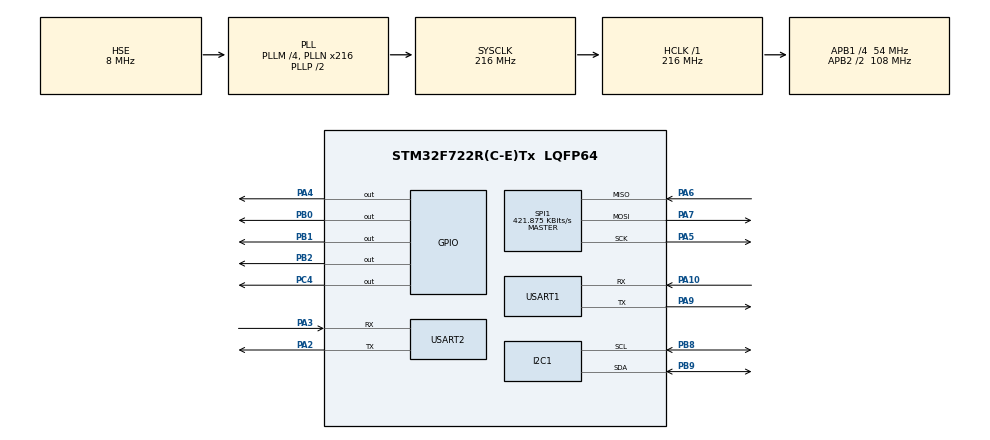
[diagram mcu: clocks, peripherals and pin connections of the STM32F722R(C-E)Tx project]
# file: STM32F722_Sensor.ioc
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CORTEX_M7.default_mode_Activation=1
FREERTOS.Tasks01=LED_FLASH,8,128,led_task,Default,NULL,Dynamic,NULL,NULL;UART_SEND,8,128,uart_task,As weak,NULL,Dynamic,NULL,NULL;IMU_DATA,8,128,imu_task,As weak,NULL,Dynamic,NULL,NULL;BARO_DATA,8,512,baro_task,As weak,NULL,Dynamic,NULL,NULL;MAG_DATA,8,128,mag_task,As weak,NULL,Dynamic,NULL,NULL
I2C1.Timing=0x20404768
Mcu.Family=STM32F7
Mcu.Name=STM32F722R(C-E)Tx
Mcu.Package=LQFP64
NVIC.PriorityGroup=NVIC_PRIORITYGROUP_4
NVIC.USART1_IRQn=true\:5\:0\:false\:false\:true\:true\:true\:true\:true
NVIC.USART2_IRQn=true\:5\:0\:false\:false\:true\:true\:true\:true\:true
PA10.Mode=Asynchronous
PA10.Signal=USART1_RX
PA2.Mode=Asynchronous
PA2.Signal=USART2_TX
PA3.Mode=Asynchronous
PA3.Signal=USART2_RX
PA4.Signal=GPIO_Output
PA5.Mode=Full_Duplex_Master
PA5.Signal=SPI1_SCK
PA6.Mode=Full_Duplex_Master
PA6.Signal=SPI1_MISO
PA7.Mode=Full_Duplex_Master
PA7.Signal=SPI1_MOSI
PA9.Mode=Asynchronous
PA9.Signal=USART1_TX
PB0.Signal=GPIO_Output
PB1.Signal=GPIO_Output
PB2.Signal=GPIO_Output
PB8.Mode=I2C
PB8.Signal=I2C1_SCL
PB9.Mode=I2C
PB9.Signal=I2C1_SDA
PC4.Signal=GPIO_Output
PH0-OSC_IN.Mode=HSE-External-Oscillator
PH0-OSC_IN.Signal=RCC_OSC_IN
PH1-OSC_OUT.Mode=HSE-External-Oscillator
PH1-OSC_OUT.Signal=RCC_OSC_OUT
ProjectManager.HeapSize=0x200
ProjectManager.StackSize=0x400
ProjectManager.TargetToolchain=STM32CubeIDE
RCC.AHBFreq_Value=216000000
RCC.APB1CLKDivider=RCC_HCLK_DIV4
RCC.APB1Freq_Value=54000000
RCC.APB1TimFreq_Value=108000000
RCC.APB2CLKDivider=RCC_HCLK_DIV2
RCC.APB2Freq_Value=108000000
RCC.APB2TimFreq_Value=216000000
RCC.CortexFreq_Value=216000000
RCC.HCLKFreq_Value=216000000
RCC.HSE_VALUE=8000000
RCC.HSI_VALUE=16000000
RCC.LSE_VALUE=32768
RCC.PLLM=4
RCC.PLLN=216
RCC.PLLSourceVirtual=RCC_PLLSOURCE_HSE
RCC.SYSCLKFreq_VALUE=216000000
RCC.SYSCLKSource=RCC_SYSCLKSOURCE_PLLCLK
RCC.USBFreq_Value=216000000
RCC.VCOOutputFreq_Value=432000000
SPI1.BaudRatePrescaler=SPI_BAUDRATEPRESCALER_256
SPI1.CalculateBaudRate=421.875 KBits/s
SPI1.DataSize=SPI_DATASIZE_8BIT
SPI1.Direction=SPI_DIRECTION_2LINES
SPI1.Mode=SPI_MODE_MASTER
SPI1.VirtualType=VM_MASTER
USART1.VirtualMode-Asynchronous=VM_ASYNC
USART2.VirtualMode-Asynchronous=VM_ASYNC
VP_FREERTOS_VS_CMSIS_V2.Mode=CMSIS_V2
board=custom

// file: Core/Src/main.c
/* USER CODE BEGIN Header */
/**
  ******************************************************************************
  * @file           : main.c
  * @brief          : Main program body
  ******************************************************************************
  * @attention
  *
  * Copyright (c) 2025 STMicroelectronics.
  * All rights reserved.
  *
  * This software is licensed under terms that can be found in the LICENSE file
  * in the root directory of this software component.
  * If no LICENSE file comes with this software, it is provided AS-IS.
  *
  ******************************************************************************
  */
/* USER CODE END Header */
#include "main.h"
#include "cmsis_os.h"
#include "i2c.h"
#include "spi.h"
#include "usart.h"
#include "gpio.h"

/* USER CODE BEGIN Includes */
#include "gyro_calibration.h"
/* USER CODE END Includes */

/* USER CODE BEGIN PV */

ist8310_data_t ist8310_data;
BMP280_CalibData bmp280_calib;

uint8_t uartdata1 = 0x01;
uint8_t uartdata2 = 0x02;
/* USER CODE END PV */

void SystemClock_Config(void);
static void MPU_Config(void);
void MX_FREERTOS_Init(void);

int main(void)
{

  /* MPU Configuration--------------------------------------------------------*/
  MPU_Config();

  /* MCU Configuration--------------------------------------------------------*/

  /* Reset of all peripherals, Initializes the Flash interface and the Systick. */
  HAL_Init();

  /* Configure the system clock */
  SystemClock_Config();

  /* Initialize all configured peripherals */
  MX_GPIO_Init();
  MX_I2C1_Init();
  MX_SPI1_Init();
  MX_USART1_UART_Init();
  MX_USART2_UART_Init();
  /* USER CODE BEGIN 2 */
  //HAL_UART_Receive_IT(&huart1, (uint8_t *)&aRxBuffer, 1);
  ICM42688_Init();

  IST8310_INIT(&hi2c1, &ist8310_data);

  BMP280_Init(&hi2c1);
  BMP280_ReadCalibrationData(&hi2c1, &bmp280_calib);

  calibrate_gyro();
  /* USER CODE END 2 */

  /* Init scheduler */
  osKernelInitialize();

  /* Call init function for freertos objects (in cmsis_os2.c) */
  MX_FREERTOS_Init();

  /* Start scheduler */
  osKernelStart();

  /* We should never get here as control is now taken by the scheduler */

  /* Infinite loop */
  while (1)
  {

  }
}

void SystemClock_Config(void)
{
  RCC_OscInitTypeDef RCC_OscInitStruct = {0};
  RCC_ClkInitTypeDef RCC_ClkInitStruct = {0};

  /** Configure the main internal regulator output voltage
  */
  __HAL_RCC_PWR_CLK_ENABLE();
  __HAL_PWR_VOLTAGESCALING_CONFIG(PWR_REGULATOR_VOLTAGE_SCALE1);

  /** Initializes the RCC Oscillators according to the specified parameters
  * in the RCC_OscInitTypeDef structure.
  */
  RCC_OscInitStruct.OscillatorType = RCC_OSCILLATORTYPE_HSE;
  RCC_OscInitStruct.HSEState = RCC_HSE_ON;
  RCC_OscInitStruct.PLL.PLLState = RCC_PLL_ON;
  RCC_OscInitStruct.PLL.PLLSource = RCC_PLLSOURCE_HSE;
  RCC_OscInitStruct.PLL.PLLM = 4;
  RCC_OscInitStruct.PLL.PLLN = 216;
  RCC_OscInitStruct.PLL.PLLP = RCC_PLLP_DIV2;
  RCC_OscInitStruct.PLL.PLLQ = 2;
  if (HAL_RCC_OscConfig(&RCC_OscInitStruct) != HAL_OK)
  {
    Error_Handler();
  }

  /** Activate the Over-Drive mode
  */
  if (HAL_PWREx_EnableOverDrive() != HAL_OK)
  {
    Error_Handler();
  }

  /** Initializes the CPU, AHB and APB buses clocks
  */
  RCC_ClkInitStruct.ClockType = RCC_CLOCKTYPE_HCLK|RCC_CLOCKTYPE_SYSCLK
                              |RCC_CLOCKTYPE_PCLK1|RCC_CLOCKTYPE_PCLK2;
  RCC_ClkInitStruct.SYSCLKSource = RCC_SYSCLKSOURCE_PLLCLK;
  RCC_ClkInitStruct.AHBCLKDivider = RCC_SYSCLK_DIV1;
  RCC_ClkInitStruct.APB1CLKDivider = RCC_HCLK_DIV4;
  RCC_ClkInitStruct.APB2CLKDivider = RCC_HCLK_DIV2;

  if (HAL_RCC_ClockConfig(&RCC_ClkInitStruct, FLASH_LATENCY_7) != HAL_OK)
  {
    Error_Handler();
  }
}

/* USER CODE BEGIN 4 */
void HAL_UART_RxCpltCallback(UART_HandleTypeDef *huart)
{
	if(huart->Instance == USART1){

	}
}
/* USER CODE END 4 */

 /* MPU Configuration */

void MPU_Config(void)
{
  MPU_Region_InitTypeDef MPU_InitStruct = {0};

  /* Disables the MPU */
  HAL_MPU_Disable();

  /** Initializes and configures the Region and the memory to be protected
  */
  MPU_InitStruct.Enable = MPU_REGION_ENABLE;
  MPU_InitStruct.Number = MPU_REGION_NUMBER0;
  MPU_InitStruct.BaseAddress = 0x0;
  MPU_InitStruct.Size = MPU_REGION_SIZE_4GB;
  MPU_InitStruct.SubRegionDisable = 0x87;
  MPU_InitStruct.TypeExtField = MPU_TEX_LEVEL0;
  MPU_InitStruct.AccessPermission = MPU_REGION_NO_ACCESS;
  MPU_InitStruct.DisableExec = MPU_INSTRUCTION_ACCESS_DISABLE;
  MPU_InitStruct.IsShareable = MPU_ACCESS_SHAREABLE;
  MPU_InitStruct.IsCacheable = MPU_ACCESS_NOT_CACHEABLE;
  MPU_InitStruct.IsBufferable = MPU_ACCESS_NOT_BUFFERABLE;

  HAL_MPU_ConfigRegion(&MPU_InitStruct);
  /* Enables the MPU */
  HAL_MPU_Enable(MPU_PRIVILEGED_DEFAULT);

}

void Error_Handler(void)
{
  __disable_irq();
  while (1)
  {
  }
}

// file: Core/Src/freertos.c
/* USER CODE BEGIN Header */
/**
  ******************************************************************************
  * File Name          : freertos.c
  * Description        : Code for freertos applications
  ******************************************************************************
  * @attention
  *
  * Copyright (c) 2025 STMicroelectronics.
  * All rights reserved.
  *
  * This software is licensed under terms that can be found in the LICENSE file
  * in the root directory of this software component.
  * If no LICENSE file comes with this software, it is provided AS-IS.
  *
  ******************************************************************************
  */
/* USER CODE END Header */

#include "FreeRTOS.h"
#include "task.h"
#include "main.h"
#include "cmsis_os.h"

/* Definitions for LED_FLASH */
osThreadId_t LED_FLASHHandle;
const osThreadAttr_t LED_FLASH_attributes = {
  .name = "LED_FLASH",
  .stack_size = 128 * 4,
  .priority = (osPriority_t) osPriorityLow,
};
/* Definitions for UART_SEND */
osThreadId_t UART_SENDHandle;
const osThreadAttr_t UART_SEND_attributes = {
  .name = "UART_SEND",
  .stack_size = 128 * 4,
  .priority = (osPriority_t) osPriorityLow,
};
/* Definitions for IMU_DATA */
osThreadId_t IMU_DATAHandle;
const osThreadAttr_t IMU_DATA_attributes = {
  .name = "IMU_DATA",
  .stack_size = 128 * 4,
  .priority = (osPriority_t) osPriorityLow,
};
/* Definitions for BARO_DATA */
osThreadId_t BARO_DATAHandle;
const osThreadAttr_t BARO_DATA_attributes = {
  .name = "BARO_DATA",
  .stack_size = 512 * 4,
  .priority = (osPriority_t) osPriorityLow,
};
/* Definitions for MAG_DATA */
osThreadId_t MAG_DATAHandle;
const osThreadAttr_t MAG_DATA_attributes = {
  .name = "MAG_DATA",
  .stack_size = 128 * 4,
  .priority = (osPriority_t) osPriorityLow,
};

void led_task(void *argument);
void uart_task(void *argument);
void imu_task(void *argument);
void baro_task(void *argument);
void mag_task(void *argument);

void MX_FREERTOS_Init(void); /* (MISRA C 2004 rule 8.1) */

void MX_FREERTOS_Init(void) {

  /* Create the thread(s) */
  /* creation of LED_FLASH */
  LED_FLASHHandle = osThreadNew(led_task, NULL, &LED_FLASH_attributes);

  /* creation of UART_SEND */
  UART_SENDHandle = osThreadNew(uart_task, NULL, &UART_SEND_attributes);

  /* creation of IMU_DATA */
  IMU_DATAHandle = osThreadNew(imu_task, NULL, &IMU_DATA_attributes);

  /* creation of BARO_DATA */
  BARO_DATAHandle = osThreadNew(baro_task, NULL, &BARO_DATA_attributes);

  /* creation of MAG_DATA */
  MAG_DATAHandle = osThreadNew(mag_task, NULL, &MAG_DATA_attributes);

}

void led_task(void *argument)
{
  /* USER CODE BEGIN led_task */
  /* Infinite loop */
  for(;;)
  {
//	  HAL_GPIO_TogglePin(GPIOB,GPIO_PIN_2);
    osDelay(500);
  }
  /* USER CODE END led_task */
}

__weak void uart_task(void *argument)
{
  for(;;)
  {
    osDelay(1);
  }
}

__weak void imu_task(void *argument)
{
  for(;;)
  {
    osDelay(1);
  }
}

__weak void baro_task(void *argument)
{
  for(;;)
  {
    osDelay(1);
  }
}

__weak void mag_task(void *argument)
{
  for(;;)
  {
    osDelay(1);
  }
}
